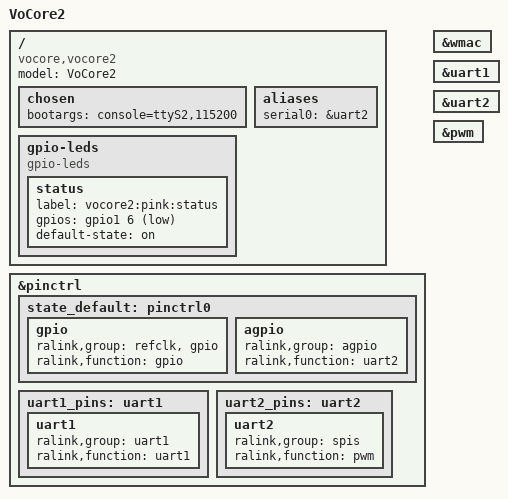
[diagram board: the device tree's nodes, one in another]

#include "mt7628an.dtsi"

#include <dt-bindings/input/input.h>

/ {
	compatible = "vocore,vocore2", "mediatek,mt7628an-soc";
	model = "VoCore2";

	chosen {
		bootargs = "console=ttyS2,115200";
	};

	aliases {
		serial0 = &uart2;
	};

	gpio-leds {
		compatible = "gpio-leds";
		status {
			label = "vocore2:pink:status";
			gpios = <&gpio1 6 1>;
			default-state = "on";
		};
	};
};

&pinctrl {
	state_default: pinctrl0 {
		gpio {
			ralink,group = "refclk", "gpio";
			ralink,function = "gpio";
		};
		agpio {
			ralink,group = "agpio";
			ralink,function = "uart2";
		};
	};
	uart1_pins: uart1 {
		uart1 {
			ralink,group = "uart1";
			ralink,function = "uart1";
		};
	};
	uart2_pins: uart2 {
		uart2 {
			ralink,group = "spis";
			ralink,function = "pwm";
		};
	};
};

&wmac {
	status = "okay";
};

&uart1 {
	status = "okay";
};

&uart2 {
	status = "okay";
};

&pwm {
	status = "okay";
};

